# CY8C5888LTI_LP097 register map
File version: 0.1
Registers are 8-bit, read-write, no defined reset value unless marked. A register's access mark holds for its fields unless they carry their own. Offsets are from the block's base; [hi:lo] are bit positions; 'fields as' and 'values as' point back to an identical list.

## Comp_low
Base 0x00000000
0x4000647F Comp_low_CONTROL_REG

## Comp_high
Base 0x00000000
0x4000647D Comp_high_CONTROL_REG

## Capture_low
Base 0x00000000
0x40006468 Capture_low_STATUS_REG
0x40006488 Capture_low_MASK_REG
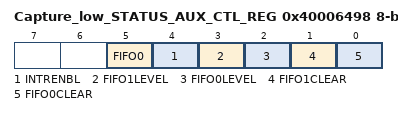
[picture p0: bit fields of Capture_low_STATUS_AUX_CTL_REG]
0x40006498 Capture_low_STATUS_AUX_CTL_REG
  [5] FIFO0 — FIFO0 clear
    1=ENABLED (Enable counter); 0=DISABLED (Disable counter)
  [4] INTRENBL — Enables or disables the Interrupt
    1=ENABLED (Interrupt enabled); 0=DISABLED (Interrupt disabled)
  [3] FIFO1LEVEL — FIFO level
    1=ENABLED (FIFO LVL: input mode: FIFO at least 1/2 empty; output mode: FIFO at least 1/2 full); 0=DISABLED (FIFO LVL: input mode: FIFO not full; output mode: FIFO not empty)
  [2] FIFO0LEVEL — FIFO level
    values as FIFO1LEVEL
  [1] FIFO1CLEAR — FIFO clear
    1=ENABLED (Clear FIFO state); 0=DISABLED (Normal FIFO operation)
  [0] FIFO0CLEAR — FIFO clear
    values as FIFO1CLEAR

## BitCounterDec
Base 0x00000000
0x4000640D BitCounterDec_COUNTER — UDB.A0 - Current Counter Value
0x4000642D BitCounterDec_PERIOD — UDB.D0 - Assigned Period
0x4000643D BitCounterDec_COMPARE — UDB.D1 - Assigned Compare Value
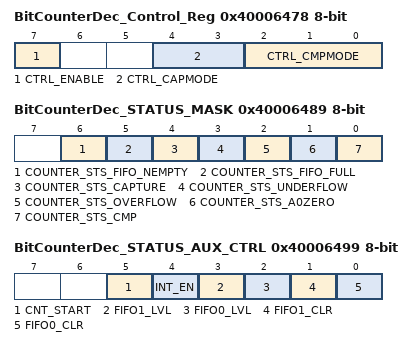
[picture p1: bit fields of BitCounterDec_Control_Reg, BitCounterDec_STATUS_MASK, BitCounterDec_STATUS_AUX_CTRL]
0x40006478 BitCounterDec_Control_Reg — UDB Control Register - Assigned Control Register Value
  [7] CTRL_ENABLE — Enable Counter
  [4:3] CTRL_CAPMODE — Capture mode
  [2:0] CTRL_CMPMODE — Compare mode
0x40006489 BitCounterDec_STATUS_MASK — UDB Status bits Interrupt Mask Enable Register
  [6] COUNTER_STS_FIFO_NEMPTY — FIFO Not Empty Status
  [5] COUNTER_STS_FIFO_FULL — FIFO Full Status
  [4] COUNTER_STS_CAPTURE — Capture Status
  [3] COUNTER_STS_UNDERFLOW — Underflow status
  [2] COUNTER_STS_OVERFLOW — Overflow status
  [1] COUNTER_STS_A0ZERO — A0 Zero ouput status
  [0] COUNTER_STS_CMP — Compare output status
0x40006499 BitCounterDec_STATUS_AUX_CTRL — UDB Auxilliary Control Register
  [5] CNT_START — FIFO0 clear
    0=E_CNT_START0 (Disable counter); 1=E_CNT_START1 (Enable counter)
  [4] INT_EN
    0=E_INT_EN0 (Interrupt disabled); 1=E_INT_EN1 (Interrupt enabled)
  [3] FIFO1_LVL — FIFO level
    0=E_FIFO_LVL_0 (FIFO LVL: input mode: FIFO not full; output mode: FIFO not empty); 1=E_FIFO_LVL_1 (FIFO LVL: input mode: FIFO at least 1/2 empty; output mode: FIFO at least 1/2 full)
  [2] FIFO0_LVL — FIFO level
    values as FIFO1_LVL
  [1] FIFO1_CLR — FIFO1 clear
    0=E_FIFO_CLR_0 (Normal FIFO operation); 1=E_FIFO_CLR_1 (Clear FIFO state)
  [0] FIFO0_CLR — FIFO0 clear
    values as FIFO1_CLR

## Waiter
Base 0x00000000
0x40006406 Waiter_COUNTER — UDB.A0 - Current Counter Value
0x40006426 Waiter_PERIOD — UDB.D0 - Assigned Period
0x40006436 Waiter_COMPARE — UDB.D1 - Assigned Compare Value
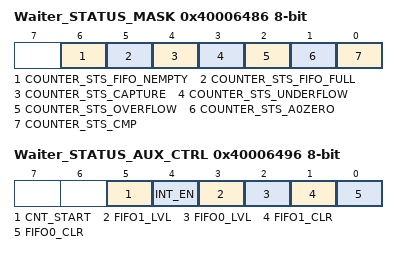
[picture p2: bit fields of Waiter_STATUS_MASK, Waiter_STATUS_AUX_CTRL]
0x40006486 Waiter_STATUS_MASK — UDB Status bits Interrupt Mask Enable Register
  [6] COUNTER_STS_FIFO_NEMPTY — FIFO Not Empty Status
  [5] COUNTER_STS_FIFO_FULL — FIFO Full Status
  [4] COUNTER_STS_CAPTURE — Capture Status
  [3] COUNTER_STS_UNDERFLOW — Underflow status
  [2] COUNTER_STS_OVERFLOW — Overflow status
  [1] COUNTER_STS_A0ZERO — A0 Zero ouput status
  [0] COUNTER_STS_CMP — Compare output status
0x40006496 Waiter_STATUS_AUX_CTRL — UDB Auxilliary Control Register
  [5] CNT_START — FIFO0 clear
    0=E_CNT_START0 (Disable counter); 1=E_CNT_START1 (Enable counter)
  [4] INT_EN
    0=E_INT_EN0 (Interrupt disabled); 1=E_INT_EN1 (Interrupt enabled)
  [3] FIFO1_LVL — FIFO level
    0=E_FIFO_LVL_0 (FIFO LVL: input mode: FIFO not full; output mode: FIFO not empty); 1=E_FIFO_LVL_1 (FIFO LVL: input mode: FIFO at least 1/2 empty; output mode: FIFO at least 1/2 full)
  [2] FIFO0_LVL — FIFO level
    values as FIFO1_LVL
  [1] FIFO1_CLR — FIFO1 clear
    0=E_FIFO_CLR_0 (Normal FIFO operation); 1=E_FIFO_CLR_1 (Clear FIFO state)
  [0] FIFO0_CLR — FIFO0 clear
    values as FIFO1_CLR
